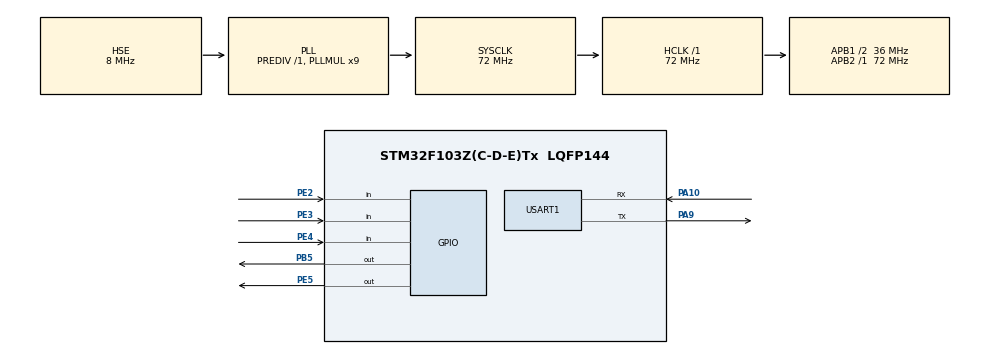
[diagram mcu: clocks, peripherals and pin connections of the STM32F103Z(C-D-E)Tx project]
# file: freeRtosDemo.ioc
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FREERTOS.Tasks01=defaultTask,0,128,StartDefaultTask,Default,NULL,Dynamic,NULL,NULL;ledTask,0,128,led_show,Default,NULL,Dynamic,NULL,NULL;uratTask,0,512,uart_com,Default,NULL,Dynamic,NULL,NULL;keyTask,0,128,key_scan,Default,NULL,Dynamic,NULL,NULL
FREERTOS.configTOTAL_HEAP_SIZE=0x2000
Mcu.Family=STM32F1
Mcu.Name=STM32F103Z(C-D-E)Tx
Mcu.Package=LQFP144
NVIC.PriorityGroup=NVIC_PRIORITYGROUP_4
NVIC.TimeBase=TIM4_IRQn
NVIC.TimeBaseIP=TIM4
OSC_IN.Mode=HSE-External-Oscillator
OSC_IN.Signal=RCC_OSC_IN
OSC_OUT.Mode=HSE-External-Oscillator
OSC_OUT.Signal=RCC_OSC_OUT
PA10.Mode=Asynchronous
PA10.Signal=USART1_RX
PA9.Mode=Asynchronous
PA9.Signal=USART1_TX
PB5.GPIO_Speed=GPIO_SPEED_FREQ_LOW
PB5.Signal=GPIO_Output
PC14-OSC32_IN.Mode=LSE-External-Oscillator
PC14-OSC32_IN.Signal=RCC_OSC32_IN
PC15-OSC32_OUT.Mode=LSE-External-Oscillator
PC15-OSC32_OUT.Signal=RCC_OSC32_OUT
PE2.Signal=GPIO_Input
PE3.Signal=GPIO_Input
PE4.Signal=GPIO_Input
PE5.PinState=GPIO_PIN_SET
PE5.Signal=GPIO_Output
ProjectManager.HeapSize=0x800
ProjectManager.StackSize=0x800
ProjectManager.TargetToolchain=MDK-ARM V5
RCC.AHBFreq_Value=72000000
RCC.APB1CLKDivider=RCC_HCLK_DIV2
RCC.APB1Freq_Value=36000000
RCC.APB1TimFreq_Value=72000000
RCC.APB2Freq_Value=72000000
RCC.APB2TimFreq_Value=72000000
RCC.HCLKFreq_Value=72000000
RCC.PLLMUL=RCC_PLL_MUL9
RCC.PLLSourceVirtual=RCC_PLLSOURCE_HSE
RCC.RTCClockSelection=RCC_RTCCLKSOURCE_LSE
RCC.SYSCLKFreq_VALUE=72000000
RCC.SYSCLKSource=RCC_SYSCLKSOURCE_PLLCLK
RCC.USBFreq_Value=72000000
USART1.VirtualMode=VM_ASYNC
VP_FREERTOS_VS_ENABLE.Mode=Enabled
VP_RTC_VS_RTC_Activate.Mode=RTC_Enabled
VP_SYS_VS_ND.Mode=No_Debug
VP_SYS_VS_tim4.Mode=TIM4
board=freeRtosDemo

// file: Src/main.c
/**
  ******************************************************************************
  * File Name          : main.c
  * Description        : Main program body
  ******************************************************************************
  * This notice applies to any and all portions of this file
  * that are not between comment pairs USER CODE BEGIN and
  * USER CODE END. Other portions of this file, whether
  * inserted by the user or by software development tools
  * are owned by their respective copyright owners.
  *
  * Copyright (c) 2017 STMicroelectronics International N.V.
  * All rights reserved.
  *
  * Redistribution and use in source and binary forms, with or without
  * modification, are permitted, provided that the following conditions are met:
  *
  * 1. Redistribution of source code must retain the above copyright notice,
  *    this list of conditions and the following disclaimer.
  * 2. Redistributions in binary form must reproduce the above copyright notice,
  *    this list of conditions and the following disclaimer in the documentation
  *    and/or other materials provided with the distribution.
  * 3. Neither the name of STMicroelectronics nor the names of other
  *    contributors to this software may be used to endorse or promote products
  *    derived from this software without specific written permission.
  * 4. This software, including modifications and/or derivative works of this
  *    software, must execute solely and exclusively on microcontroller or
  *    microprocessor devices manufactured by or for STMicroelectronics.
  * 5. Redistribution and use of this software other than as permitted under
  *    this license is void and will automatically terminate your rights under
  *    this license.
  *
  * THIS SOFTWARE IS PROVIDED BY STMICROELECTRONICS AND CONTRIBUTORS "AS IS"
  * AND ANY EXPRESS, IMPLIED OR STATUTORY WARRANTIES, INCLUDING, BUT NOT
  * LIMITED TO, THE IMPLIED WARRANTIES OF MERCHANTABILITY, FITNESS FOR A
  * PARTICULAR PURPOSE AND NON-INFRINGEMENT OF THIRD PARTY INTELLECTUAL PROPERTY
  * RIGHTS ARE DISCLAIMED TO THE FULLEST EXTENT PERMITTED BY LAW. IN NO EVENT
  * SHALL STMICROELECTRONICS OR CONTRIBUTORS BE LIABLE FOR ANY DIRECT, INDIRECT,
  * INCIDENTAL, SPECIAL, EXEMPLARY, OR CONSEQUENTIAL DAMAGES (INCLUDING, BUT NOT
  * LIMITED TO, PROCUREMENT OF SUBSTITUTE GOODS OR SERVICES; LOSS OF USE, DATA,
  * OR PROFITS; OR BUSINESS INTERRUPTION) HOWEVER CAUSED AND ON ANY THEORY OF
  * LIABILITY, WHETHER IN CONTRACT, STRICT LIABILITY, OR TORT (INCLUDING
  * NEGLIGENCE OR OTHERWISE) ARISING IN ANY WAY OUT OF THE USE OF THIS SOFTWARE,
  * EVEN IF ADVISED OF THE POSSIBILITY OF SUCH DAMAGE.
  *
  ******************************************************************************
  */
#include "main.h"
#include "stm32f1xx_hal.h"
#include "cmsis_os.h"
#include "rtc.h"
#include "usart.h"
#include "gpio.h"

/* USER CODE BEGIN PV */
/* Private variables ---------------------------------------------------------*/

/* USER CODE END PV */

void SystemClock_Config(void);
void MX_FREERTOS_Init(void);

/* USER CODE BEGIN PFP */
/* Private function prototypes -----------------------------------------------*/

/* USER CODE END PFP */

int main(void)
{

  /* MCU Configuration----------------------------------------------------------*/

  /* Reset of all peripherals, Initializes the Flash interface and the Systick. */
  HAL_Init();

  /* Configure the system clock */
  SystemClock_Config();

  /* Initialize all configured peripherals */
  MX_GPIO_Init();
  MX_RTC_Init();
  MX_USART1_UART_Init();

  /* Call init function for freertos objects (in freertos.c) */
  MX_FREERTOS_Init();

  /* Start scheduler */
  osKernelStart();

  /* We should never get here as control is now taken by the scheduler */

  /* Infinite loop */
  while (1)
  {

  }

}

/** System Clock Configuration
*/
void SystemClock_Config(void)
{

  RCC_OscInitTypeDef RCC_OscInitStruct;
  RCC_ClkInitTypeDef RCC_ClkInitStruct;
  RCC_PeriphCLKInitTypeDef PeriphClkInit;

    /**Initializes the CPU, AHB and APB busses clocks
    */
  RCC_OscInitStruct.OscillatorType = RCC_OSCILLATORTYPE_HSE|RCC_OSCILLATORTYPE_LSE;
  RCC_OscInitStruct.HSEState = RCC_HSE_ON;
  RCC_OscInitStruct.HSEPredivValue = RCC_HSE_PREDIV_DIV1;
  RCC_OscInitStruct.LSEState = RCC_LSE_ON;
  RCC_OscInitStruct.HSIState = RCC_HSI_ON;
  RCC_OscInitStruct.PLL.PLLState = RCC_PLL_ON;
  RCC_OscInitStruct.PLL.PLLSource = RCC_PLLSOURCE_HSE;
  RCC_OscInitStruct.PLL.PLLMUL = RCC_PLL_MUL9;
  if (HAL_RCC_OscConfig(&RCC_OscInitStruct) != HAL_OK)
  {
    _Error_Handler(__FILE__, __LINE__);
  }

    /**Initializes the CPU, AHB and APB busses clocks
    */
  RCC_ClkInitStruct.ClockType = RCC_CLOCKTYPE_HCLK|RCC_CLOCKTYPE_SYSCLK
                              |RCC_CLOCKTYPE_PCLK1|RCC_CLOCKTYPE_PCLK2;
  RCC_ClkInitStruct.SYSCLKSource = RCC_SYSCLKSOURCE_PLLCLK;
  RCC_ClkInitStruct.AHBCLKDivider = RCC_SYSCLK_DIV1;
  RCC_ClkInitStruct.APB1CLKDivider = RCC_HCLK_DIV2;
  RCC_ClkInitStruct.APB2CLKDivider = RCC_HCLK_DIV1;

  if (HAL_RCC_ClockConfig(&RCC_ClkInitStruct, FLASH_LATENCY_2) != HAL_OK)
  {
    _Error_Handler(__FILE__, __LINE__);
  }

  PeriphClkInit.PeriphClockSelection = RCC_PERIPHCLK_RTC;
  PeriphClkInit.RTCClockSelection = RCC_RTCCLKSOURCE_LSE;
  if (HAL_RCCEx_PeriphCLKConfig(&PeriphClkInit) != HAL_OK)
  {
    _Error_Handler(__FILE__, __LINE__);
  }

    /**Configure the Systick interrupt time
    */
  HAL_SYSTICK_Config(HAL_RCC_GetHCLKFreq()/1000);

    /**Configure the Systick
    */
  HAL_SYSTICK_CLKSourceConfig(SYSTICK_CLKSOURCE_HCLK);

  /* SysTick_IRQn interrupt configuration */
  HAL_NVIC_SetPriority(SysTick_IRQn, 15, 0);
}

void HAL_TIM_PeriodElapsedCallback(TIM_HandleTypeDef *htim)
{
  if (htim->Instance == TIM4) {
    HAL_IncTick();
  }
}

void _Error_Handler(char * file, int line)
{
  while(1)
  {
  }
}

/************************ (C) COPYRIGHT STMicroelectronics *****END OF FILE****/

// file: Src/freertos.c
/**
  ******************************************************************************
  * File Name          : freertos.c
  * Description        : Code for freertos applications
  ******************************************************************************
  * This notice applies to any and all portions of this file
  * that are not between comment pairs USER CODE BEGIN and
  * USER CODE END. Other portions of this file, whether
  * inserted by the user or by software development tools
  * are owned by their respective copyright owners.
  *
  * Copyright (c) 2017 STMicroelectronics International N.V.
  * All rights reserved.
  *
  * Redistribution and use in source and binary forms, with or without
  * modification, are permitted, provided that the following conditions are met:
  *
  * 1. Redistribution of source code must retain the above copyright notice,
  *    this list of conditions and the following disclaimer.
  * 2. Redistributions in binary form must reproduce the above copyright notice,
  *    this list of conditions and the following disclaimer in the documentation
  *    and/or other materials provided with the distribution.
  * 3. Neither the name of STMicroelectronics nor the names of other
  *    contributors to this software may be used to endorse or promote products
  *    derived from this software without specific written permission.
  * 4. This software, including modifications and/or derivative works of this
  *    software, must execute solely and exclusively on microcontroller or
  *    microprocessor devices manufactured by or for STMicroelectronics.
  * 5. Redistribution and use of this software other than as permitted under
  *    this license is void and will automatically terminate your rights under
  *    this license.
  *
  * THIS SOFTWARE IS PROVIDED BY STMICROELECTRONICS AND CONTRIBUTORS "AS IS"
  * AND ANY EXPRESS, IMPLIED OR STATUTORY WARRANTIES, INCLUDING, BUT NOT
  * LIMITED TO, THE IMPLIED WARRANTIES OF MERCHANTABILITY, FITNESS FOR A
  * PARTICULAR PURPOSE AND NON-INFRINGEMENT OF THIRD PARTY INTELLECTUAL PROPERTY
  * RIGHTS ARE DISCLAIMED TO THE FULLEST EXTENT PERMITTED BY LAW. IN NO EVENT
  * SHALL STMICROELECTRONICS OR CONTRIBUTORS BE LIABLE FOR ANY DIRECT, INDIRECT,
  * INCIDENTAL, SPECIAL, EXEMPLARY, OR CONSEQUENTIAL DAMAGES (INCLUDING, BUT NOT
  * LIMITED TO, PROCUREMENT OF SUBSTITUTE GOODS OR SERVICES; LOSS OF USE, DATA,
  * OR PROFITS; OR BUSINESS INTERRUPTION) HOWEVER CAUSED AND ON ANY THEORY OF
  * LIABILITY, WHETHER IN CONTRACT, STRICT LIABILITY, OR TORT (INCLUDING
  * NEGLIGENCE OR OTHERWISE) ARISING IN ANY WAY OUT OF THE USE OF THIS SOFTWARE,
  * EVEN IF ADVISED OF THE POSSIBILITY OF SUCH DAMAGE.
  *
  ******************************************************************************
  */

#include "FreeRTOS.h"
#include "task.h"
#include "cmsis_os.h"

/* USER CODE BEGIN Includes */
#include "stm32f1xx_hal.h"

/* USER CODE END Includes */

osThreadId defaultTaskHandle;
osThreadId ledTaskHandle;
osThreadId uratTaskHandle;
osThreadId keyTaskHandle;

/* USER CODE BEGIN Variables */

uint8_t key_vlaue=0;

/* USER CODE END Variables */

void StartDefaultTask(void const * argument);
void led_show(void const * argument);
void uart_com(void const * argument);
void key_scan(void const * argument);

void MX_FREERTOS_Init(void); /* (MISRA C 2004 rule 8.1) */

/* Hook prototypes */

/* Init FreeRTOS */

void MX_FREERTOS_Init(void) {

  /* Create the thread(s) */
  /* definition and creation of defaultTask */
  osThreadDef(defaultTask, StartDefaultTask, osPriorityNormal, 0, 128);
  defaultTaskHandle = osThreadCreate(osThread(defaultTask), NULL);

  /* definition and creation of ledTask */
  osThreadDef(ledTask, led_show, osPriorityNormal, 0, 128);
  ledTaskHandle = osThreadCreate(osThread(ledTask), NULL);

  /* definition and creation of uratTask */
  osThreadDef(uratTask, uart_com, osPriorityNormal, 0, 512);
  uratTaskHandle = osThreadCreate(osThread(uratTask), NULL);

  /* definition and creation of keyTask */
  osThreadDef(keyTask, key_scan, osPriorityNormal, 0, 128);
  keyTaskHandle = osThreadCreate(osThread(keyTask), NULL);

}

/* StartDefaultTask function */
void StartDefaultTask(void const * argument)
{

  for(;;)
  {
    osDelay(1);
  }
}

/* led_show function */
void led_show(void const * argument)
{
  /* USER CODE BEGIN led_show */
  /* Infinite loop */
  for(;;)
  {
		HAL_GPIO_TogglePin(GPIOE,GPIO_PIN_5);
    osDelay(500);
  }
  /* USER CODE END led_show */
}

/* uart_com function */
void uart_com(void const * argument)
{
  /* USER CODE BEGIN uart_com */
  /* Infinite loop */
  for(;;)
  {
		HAL_GPIO_TogglePin(GPIOB,GPIO_PIN_5);
//		switch(key_vlaue){
//
//			case 0:
//				printf("key 1 push down\r\n");
//			break;
//
//			case 1:
//				printf("key 2 push down\r\n");
//			break;
//
//			case 2:
//				printf("key 3 push down\r\n");
//			break;
//
//			default: break;
//
//		}
    osDelay(50);
  }
  /* USER CODE END uart_com */
}

/* key_scan function */
void key_scan(void const * argument)
{
  for(;;)
  {
    osDelay(1);
  }
}

/************************ (C) COPYRIGHT STMicroelectronics *****END OF FILE****/
